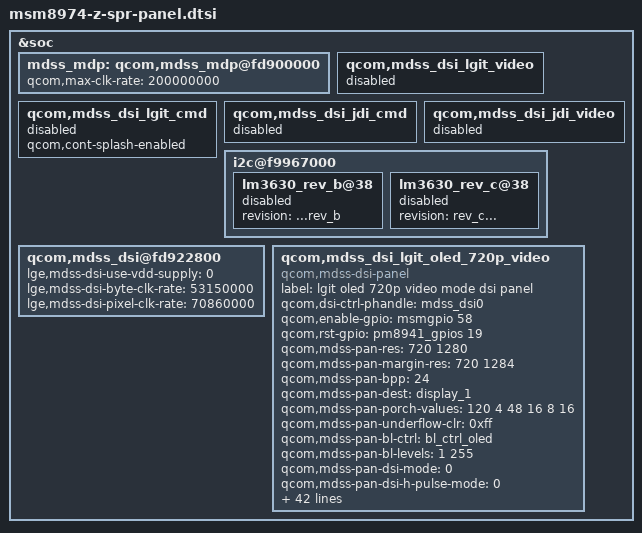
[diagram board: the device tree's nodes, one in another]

/* Copyright (c) 2012, Code Aurora Forum. All rights reserved.
 *
 * This program is free software; you can redistribute it and/or modify
 * it under the terms of the GNU General Public License version 2 and
 * only version 2 as published by the Free Software Foundation.
 *
 * This program is distributed in the hope that it will be useful,
 * but WITHOUT ANY WARRANTY; without even the implied warranty of
 * MERCHANTABILITY or FITNESS FOR A PARTICULAR PURPOSE.  See the
 * GNU General Public License for more details.
 */

&soc {
	mdss_mdp: qcom,mdss_mdp@fd900000 {
		qcom,max-clk-rate = <200000000>;
	};
	qcom,mdss_dsi_lgit_video {
		status = "disable";
	};
	qcom,mdss_dsi_lgit_cmd {
		status = "disable";
		qcom,cont-splash-enabled;
	};
	qcom,mdss_dsi_jdi_cmd {
		status = "disable";
	};
	qcom,mdss_dsi_jdi_video {
		status = "disable";
	};
	i2c@f9967000 {
		lm3630_rev_b@38 {
			status = "disable";
			revision = "...rev_b";
		};

		lm3630_rev_c@38 {
			status = "disable";
			revision = "rev_c...";
		};
	};
	qcom,mdss_dsi@fd922800 {
		lge,mdss-dsi-use-vdd-supply = <0>;
		lge,mdss-dsi-byte-clk-rate = <53150000>;
		lge,mdss-dsi-pixel-clk-rate = <70860000>;
	};

	qcom,mdss_dsi_lgit_oled_720p_video {
		compatible = "qcom,mdss-dsi-panel";
		label = "lgit oled 720p video mode dsi panel";
		status = "ok";
		qcom,dsi-ctrl-phandle = <&mdss_dsi0>;
		qcom,enable-gpio = <&msmgpio 58 0>;  // dsv disable because the dsv is handled with LCD panel . daewoo.kwak Z bring up 2012 11 26 
		qcom,rst-gpio = <&pm8941_gpios 19 0>;
		qcom,mdss-pan-res = <720 1280>;
		qcom,mdss-pan-margin-res = <720 1284>;
		qcom,mdss-pan-bpp = <24>;
		qcom,mdss-pan-dest = "display_1";
		qcom,mdss-pan-porch-values =<120 4 48 16 8 16>;// <88 4 32 4 8 4>; //<112 4 156 8 16 8>; // <88 4 32 8 16 8>; // <20 4 20 4 2 4>; // <189 4 200 4 2 4>;
		qcom,mdss-pan-underflow-clr = <0xff>;
		qcom,mdss-pan-bl-ctrl = "bl_ctrl_oled"; // bl-ctrl changed because of the oled . daewoo.kwak Z bring up 2012 11 26 
		qcom,mdss-pan-bl-levels = <1 255>;
		qcom,mdss-pan-dsi-mode = <0>;
		qcom,mdss-pan-dsi-h-pulse-mode = <0>;
		qcom,mdss-pan-dsi-h-power-stop = <0 0 0>;
		qcom,mdss-pan-dsi-bllp-power-stop = <1 1>;
		qcom,mdss-pan-dsi-traffic-mode = <1>;
		qcom,mdss-pan-dsi-dst-format = <3>;
		qcom,mdss-pan-dsi-vc = <0>;
		qcom,mdss-pan-dsi-rgb-swap = <0>;
		qcom,mdss-pan-dsi-data-lanes = <1 1 1 1>;
                qcom,mdss-pan-dsi-dlane-swap = <0>;
		qcom,mdss-pan-dsi-t-clk = <0x2B 0x1F>;
		qcom,mdss-pan-dsi-stream = <0>;
		qcom,mdss-pan-dsi-mdp-tr = <0x0>;
		qcom,mdss-pan-dsi-dma-tr = <0x04>;
		qcom,mdss-pan-frame-rate = <60>;
		qcom,panel-phy-regulatorSettings = [03 01 01 00  /* Regualotor settings */
						    20 00 01];
		qcom,panel-phy-timingSettings = [6D 24 19 00 34 2F
						    1E 26 2A 03 04 00];
						    				    

		qcom,panel-phy-strengthCtrl = [77 06];
		qcom,panel-phy-bistCtrl = [00 00 b1 ff           /* BIST Ctrl settings */
					   00 00];
		qcom,panel-phy-laneConfig = [
			00 c2 45 00 00 00 00 01 75 // lane0 config
			00 c2 45 00 00 00 00 01 75 // lane1 config
			00 c2 45 00 00 00 00 01 75 // lane2 config
			00 c2 45 00 00 00 00 01 75 // lane3 config
			00 02 45 00 00 00 00 01 97 // Clk ln config
		];
		
		qcom,panel-on-cmds = [
			15 01 00 00 12 00 02 B0 AC // MCS access
			05 01 00 00 37 00 02 11 00 // Sleep Out : delay 55ms
			39 01 00 00 22 00 14 ED 0F 00 00 30 6E 30 6E 39 6E 39 6E 00 23 30 53 29 6E 29 6E // timing control
			15 01 00 00 00 00 02 51 00 //
			15 01 00 00 00 00 02 53 20 // Display Control Register
			05 01 00 00 00 00 02 29 00 // Display on
		];
		qcom,on-cmds-dsi-state = "DSI_LP_MODE";
		qcom,panel-off-cmds = [
			05 01 00 00 00 00 02 28 00 // Display off
			05 01 00 00 78 00 02 10 00 // Sleep In : delay 7frames
		];
		qcom,off-cmds-dsi-state = "DSI_HS_MODE";

	      qcom,blmap_size = <256>;
	      qcom,blmap = <
		     0   // Minimum brightness for Chargerlogo sleep
		     108 108 108 108 108 108 108 109 109 109 109 109 109 109 109
		     109 110 110 110 110 110 110 111 111 111 111 111 111 112 112
		     113 114 115 116 117 117 118 118 119 119 119 120 121 121 123
		     124 124 125 125 125 126 126 127 127 130 131 131 132 132 133
		     133 134 134 135 135 136 137 137 138 139 139 140 140 141 141
		     142 142 143 143 144 146 147 148 149 150 150 151 152 152 153
		     154 154 155 155 156 156 156 157 158 158 159 159 160 161 161
		     162 163 164 165 166 167 168 169 169 170 170 171 172 173 174
		     174 175 175 176 176 177 177 178 178 179 180 181 182 182 183
		     184 185 185 186 186 187 187 188 188 189 190 191 192 192 193
		     194 194 195 195 196 196 197 197 198 198 199 199 200 200 201
		     201 202 202 203 203 203 205 206 208 208 208 209 210 210 211
		     211 212 213 214 214 215 215 216 217 218 218 219 219 220 220
		     221 221 222 222 223 224 225 225 226 226 227 227 228 228 229
		     229 230 231 231 232 232 233 233 234 234 235 236 237 237 238
		     238 239 240 240 241 241 242 243 244 244 245 245 246 246 247
		     247 248 248 249 249 250 250 251 252 253 253 254 254 255 255
              >;
		
		/* image tuning cmds set */
		// CM mode0 : Normal & Sharpness (echo 0)
		lge,img-tune-cmds-cm0 = [
			15 01 00 00 00 00 02 55 44 
			39 01 00 00 00 00 19 E1 80 80 80 80 80 80 80 80 80 80 80 80 80 80 80 6A 70 7A 80 80 80 80 80 80
			39 01 00 00 00 00 19 E2 7F 7F 7F 7F 7F 7F 7F 7F 7F 7F 7F 7F FF FF FF FF FF FF FF FF FF FF FF FF
		];
		// CM mode0 : Normal & Sharpness (echo 1)
		// add PLC 60% on and CACC
		lge,img-tune-cmds-ce-cm0-plc60 = [
			15 01 00 00 00 00 02 55 75 
			39 01 00 00 00 00 07 D5 1E 28 72 01 00 01 // Threshold 40 2013-05-20 : LGD
			39 01 00 00 00 00 21 D6 FE F9 F4 EE EA E3 DA D7 FD FB F6 F3 EE EB E6 E2 FE FB F9 F7 F4 F1 EF EC FF FF FF FF FF FF FF FF // ACL LUT 2013-05-20 : LGD
			39 01 00 00 00 00 14 C5 00 20 51 03 03 03 00 80 80 00 00 10 00 50 40 40 60 80 80 // CE_CACC 2013-06-08
			39 01 00 00 00 00 19 E1 80 80 80 80 80 80 80 80 80 80 80 80 80 80 80 6A 70 7A 80 80 80 80 80 80
			39 01 00 00 00 00 19 E2 7F 7F 7F 7F 7F 7F 7F 7F 7F 7F 7F 7F FF FF FF FF FF FF FF FF FF FF FF FF
		];
		// CM mode1 : Vivid & Sharpness (echo 2)
		lge,img-tune-cmds-cm1 = [
			15 01 00 00 00 00 02 55 C4 // add gamma enable
			39 01 00 00 00 00 19 E1 80 80 80 80 80 80 80 80 80 80 80 80 80 80 80 6A 70 7A 80 80 80 80 80 80 // SET CM PARAMETER0
			39 01 00 00 00 00 19 E2 7F 7F 7F 7F 7F 7F 7F 7F 7F 7F 7F 7F FF FF FF FF FF FF FF FF FF FF FF FF // SET CM PARAMETER1
			39 01 00 00 00 00 11 C9 32 3A 46 4E 4E 46 3A 32 00 FC F0 E4 E0 F8 1C 38 // add gamma LUT
			39 01 00 00 00 00 11 CA 32 3A 46 4E 4E 46 3A 32 00 FC F0 E4 E0 F8 1C 38
			39 01 00 00 00 00 11 CB 32 3A 46 4E 4E 46 3A 32 00 FC F0 E4 E0 F8 1C 38
		];
		// CM mode1 : Vivid & Sharpness (echo 3)
		// add PLC 60% on and CACC
		lge,img-tune-cmds-ce-cm1-plc60 = [
			15 01 00 00 00 00 02 55 F5 // add gamma enable
			39 01 00 00 00 00 07 D5 1E 28 72 01 00 01 // Threshold 40 2013-05-20 : LGD
			39 01 00 00 00 00 21 D6 FE F9 F4 EE EA E3 DA D7 FD FB F6 F3 EE EB E6 E2 FE FB F9 F7 F4 F1 EF EC FF FF FF FF FF FF FF FF // ACL LUT 2013-05-20 : LGD
			39 01 00 00 00 00 14 C5 00 20 51 03 03 03 00 80 80 00 00 10 00 50 40 40 60 80 80 // CE_CACC 2013-06-08
			39 01 00 00 00 00 19 E1 80 80 80 80 80 80 80 80 80 80 80 80 80 80 80 6A 70 7A 80 80 80 80 80 80 // SET CM PARAMETER0
			39 01 00 00 00 00 19 E2 7F 7F 7F 7F 7F 7F 7F 7F 7F 7F 7F 7F FF FF FF FF FF FF FF FF FF FF FF FF // SET CM PARAMETER1
			
			39 01 00 00 00 00 11 C9 32 3A 46 4E 4E 46 3A 32 00 FC F0 E4 E0 F8 1C 38 // add gamma LUT
			39 01 00 00 00 00 11 CA 32 3A 46 4E 4E 46 3A 32 00 FC F0 E4 E0 F8 1C 38
			39 01 00 00 00 00 11 CB 32 3A 46 4E 4E 46 3A 32 00 FC F0 E4 E0 F8 1C 38
		];
		// CM mode2 : Natural & Sharpness (echo 4)
		lge,img-tune-cmds-cm2 = [
			15 01 00 00 00 00 02 55 44
			39 01 00 00 00 00 19 E1 80 82 83 88 8F 85 83 88 8F 8A 85 80 80 7A 6C 5D 5A 64 5D 43 43 62 75 80 // SET CM PARAMETER0
			39 01 00 00 00 00 19 E2 7F 7F 7F 7F 7F 7F 7F 7F 7F 7F 7F 7F FF FF FF FF FF FF FF DA DA FF FF FF // SET CM PARAMETER1
		];
		// CM mode2 : Natural & Sharpness (echo 5)
		// add PLC 60% on and CACC
		lge,img-tune-cmds-ce-cm2-plc60 = [
			15 01 00 00 00 00 02 55 75
			39 01 00 00 00 00 07 D5 1E 28 72 01 00 01 // Threshold 40 2013-05-20 : LGD
			39 01 00 00 00 00 21 D6 FE F9 F4 EE EA E3 DA D7 FD FB F6 F3 EE EB E6 E2 FE FB F9 F7 F4 F1 EF EC FF FF FF FF FF FF FF FF // ACL LUT 2013-05-20 : LGD
			39 01 00 00 00 00 14 C5 00 20 51 03 03 03 00 80 80 00 00 10 00 50 40 40 60 80 80 // CE_CACC 2013-06-08
			39 01 00 00 00 00 19 E1 80 82 83 88 8F 85 83 88 8F 8A 85 80 80 7A 6C 5D 5A 64 5D 43 43 62 75 80 // SET CM PARAMETER0
			39 01 00 00 00 00 19 E2 7F 7F 7F 7F 7F 7F 7F 7F 7F 7F 7F 7F FF FF FF FF FF FF FF DA DA FF FF FF // SET CM PARAMETER1
		];

	};
};
